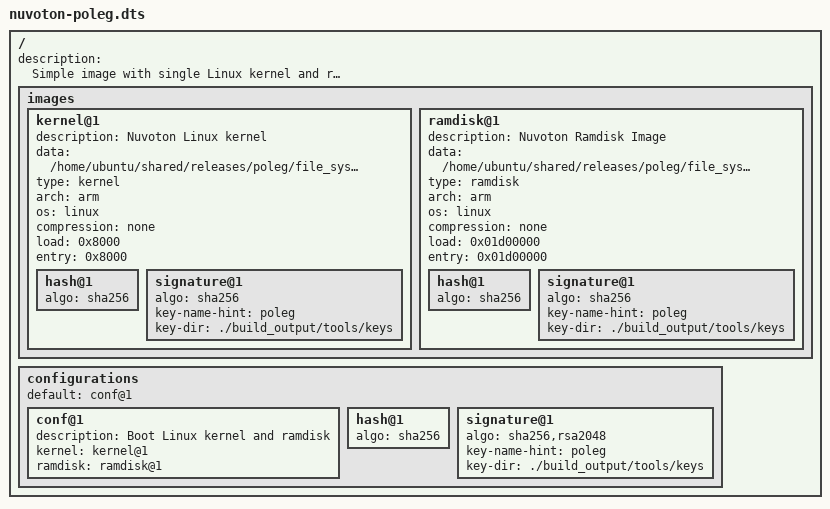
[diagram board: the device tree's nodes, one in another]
/dts-v1/;
/ {
	description = "Simple image with single Linux kernel and ramdisk";
	#address-cells = <0x1>;

	images {
        kernel@1 {
            description = "Nuvoton Linux kernel";
            data = /incbin/("/home/ubuntu/shared/releases/poleg/file_sys/4112.01.13/dual/deliverables/PolegSVB/zImage");
            type = "kernel";
            arch = "arm";
            os = "linux";
            compression = "none";
            load = <0x8000>;
            entry = <0x8000>;
            hash@1 {
                algo = "sha256";
            };
	    signature@1 {
                algo = "sha256";
                key-name-hint = "poleg";
                key-dir = "./build_output/tools/keys";
            };
        };
        ramdisk@1 {
            description = "Nuvoton Ramdisk Image";
            data = /incbin/("/home/ubuntu/shared/releases/poleg/file_sys/4112.01.13/dual/deliverables/PolegSVB/romfs.img.gz");
            type = "ramdisk";
            arch = "arm";
            os = "linux";
            compression = "none";
            load = <0x01d00000>;
            entry = <0x01d00000>;
            hash@1 {
                algo = "sha256";
            };
	    signature@1 {
                algo = "sha256";
                key-name-hint = "poleg";
                key-dir = "./build_output/tools/keys";
            };
       };
	};
	configurations {
        default = "conf@1";
        conf@1 {
            description = "Boot Linux kernel and ramdisk";
            kernel = "kernel@1";
            ramdisk = "ramdisk@1";
        };
        hash@1 {
                algo = "sha256";
        };
		signature@1 {
            algo = "sha256,rsa2048";
            key-name-hint = "poleg";
            key-dir = "./build_output/tools/keys";
        };
	};
};
